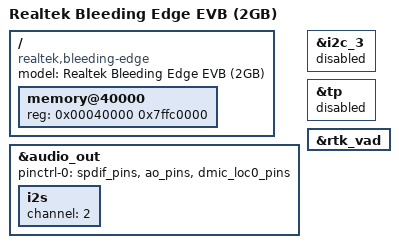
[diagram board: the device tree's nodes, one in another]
// SPDX-License-Identifier: (GPL-2.0-or-later OR BSD-2-Clause)
/*
 * Copyright (c) 2020 Realtek Semiconductor Corp.
 */

/dts-v1/;

#include "rtd1619b-bleedingedge.dtsi"

/ {
	compatible = "realtek,bleeding-edge", "realtek,rtd1619b";
	model = "Realtek Bleeding Edge EVB (2GB)";

	memory@40000 {
		device_type = "memory";
		reg = <0x00040000 0x7ffc0000>; /* 2 GB */
	};
};

&audio_out {
	pinctrl-0 = <&spdif_pins>, <&ao_pins>, <&dmic_loc0_pins>;
	i2s {
		status = "okay";
		channel = <2>;
	};
};

&i2c_3 {
	status = "disabled";
};

&tp {
	status = "disabled";
};

&rtk_vad {
	status = "okay";
};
